# MPU_356.0 register map
Vendor: Texas Instruments
Peripheral module from a debugger description file (folder MSP432).
Registers are 32-bit, access not given, no defined reset value unless marked. A register's access mark holds for its fields unless they carry their own. Offsets are as the file gives them; lines under a group give offsets from that group; [hi:lo] are bit positions; {n}, {i} and the like mark numbered series; 'fields as' and 'values as' point back to an identical list; <NAME> marks a mode.

## MPU
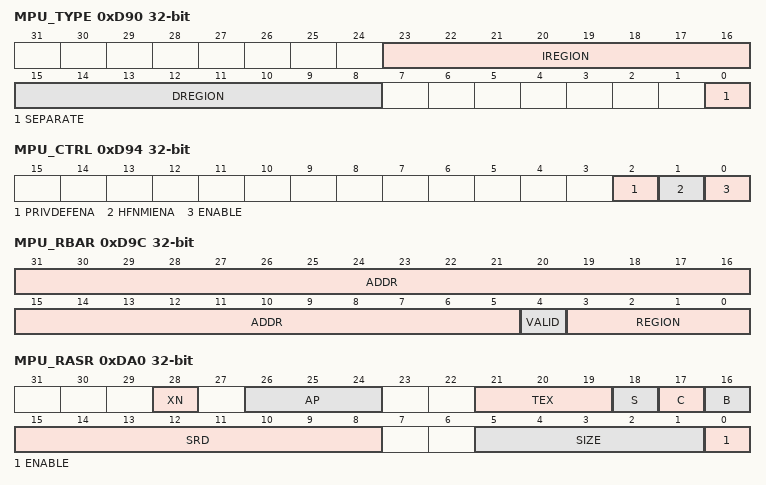
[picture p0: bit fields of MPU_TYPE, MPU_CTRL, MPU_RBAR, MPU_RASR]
0xD90 MPU_TYPE ro
  [23:16] IREGION — Because the processor core uses only a unified MPU, IREGION always contains 0x00.
  [15:8] DREGION — Number of supported MPU regions field. DREGION contains 0x08 if the implementation contains an MPU indicating eight MPU regions, otherwise it contains 0x00.
  [0] SEPARATE — Because the processor core uses only a unified MPU, SEPARATE is always 0.
0xD94 MPU_CTRL rw — MPU Control Register
  [2] PRIVDEFENA — This bit enables the default memory map for privileged access, as a background region, when the MPU is enabled. The background region acts as if it was region number 1 before any settable regions. Any region that is set up overlays this default map, and overrides it. If this bit = 0, the default memory map is disabled, and memory not covered by a region faults. This applies to memory type, Execute Never (XN), cache and shareable rules. However, this only applies to privileged mode (fetch and data access). User mode code faults unless a region has been set up for its code and data. When the MPU is disabled, the default map acts on both privileged and user mode code. XN and SO rules always apply to the System partition whether this enable is set or not. If the MPU is disabled, this bit is ignored. Reset clears the PRIVDEFENA bit.
  [1] HFNMIENA — This bit enables the MPU when in Hard Fault, NMI, and FAULTMASK escalated handlers. If this bit = 1 and the ENABLE bit = 1, the MPU is enabled when in these handlers. If this bit = 0, the MPU is disabled when in these handlers, regardless of the value of ENABLE. If this bit =1 and ENABLE = 0, behavior is Unpredictable. Reset clears the HFNMIENA bit.
  [0] ENABLE — MPU enable bit. Reset clears the ENABLE bit.
    0=en_0b0 (disable MPU); 1=en_0b1 (enable MPU)
0xD98 MPU_RNR rw — MPU Region Number Register
  [7:0] REGION — Region select field. Selects the region to operate on when using the Region Attribute and Size Register and the Region Base Address Register. It must be written first except when the address VALID + REGION fields are written, which overwrites this.
0xD9C MPU_RBAR rw — MPU Region Base Address Register
  [31:5] ADDR — Region base address field. The position of the LSB depends on the region size, so that the base address is aligned according to an even multiple of size. The power of 2 size specified by the SZENABLE field of the MPU Region Attribute and Size Register defines how many bits of base address are used.
  [4] VALID — MPU Region Number valid bit.
    0=en_0b0 (MPU Region Number Register remains unchanged and is interpreted.); 1=en_0b1 (MPU Region Number Register is overwritten by bits 3:0 (the REGION value).)
  [3:0] REGION — MPU region override field.
0xDA0 MPU_RASR rw — MPU Region Attribute and Size Register
  [28] XN — Instruction access disable bit
    0=en_0b0 (enable instruction fetches); 1=en_0b1 (disable instruction fetches)
  [26:24] AP — Data access permission field
    0=en_0b000 (Priviliged permissions: No access. User permissions: No access.); 1=en_0b001 (Priviliged permissions: Read-write. User permissions: No access.); 2=en_0b010 (Priviliged permissions: Read-write. User permissions: Read-only.); 3=en_0b011 (Priviliged permissions: Read-write. User permissions: Read-write.); 5=en_0b101 (Priviliged permissions: Read-only. User permissions: No access.); 6=en_0b110 (Priviliged permissions: Read-only. User permissions: Read-only.); 7=en_0b111 (Priviliged permissions: Read-only. User permissions: Read-only.)
  [21:19] TEX — Type extension field
  [18] S — Shareable bit
    0=en_0b0 (not shareable); 1=en_0b1 (shareable)
  [17] C — Cacheable bit
    0=en_0b0 (not cacheable); 1=en_0b1 (cacheable)
  [16] B — Bufferable bit
    0=en_0b0 (not bufferable); 1=en_0b1 (bufferable)
  [15:8] SRD — Sub-Region Disable (SRD) field. Setting an SRD bit disables the corresponding sub-region. Regions are split into eight equal-sized sub-regions. Sub-regions are not supported for region sizes of 128 bytes and less.
  [5:1] SIZE — MPU Protection Region Size Field.
    0=en_0b00000 (Reserved); 1=en_0b00001 (Reserved); 2=en_0b00010 (Reserved); 3=en_0b00011 (Reserved); 4=en_0b00100 (32B); 5=en_0b00101 (64B); 6=en_0b00110 (128B); 7=en_0b00111 (256B); 8=en_0b01000 (512B); 9=en_0b01001 (1KB); 10=en_0b01010 (2KB); 11=en_0b01011 (4KB); 12=en_0b01100 (8KB); 13=en_0b01101 (16KB); 14=en_0b01110 (32KB); 15=en_0b01111 (64KB); 16=en_0b10000 (128KB); 17=en_0b10001 (256KB); 18=en_0b10010 (512KB); 19=en_0b10011 (1MB); 20=en_0b10100 (2MB); 21=en_0b10101 (4MB); 22=en_0b10110 (8MB); 23=en_0b10111 (16MB); 24=en_0b11000 (32MB); 25=en_0b11001 (64MB); 26=en_0b11010 (128MB); 27=en_0b11011 (256MB); 28=en_0b11100 (512MB); 29=en_0b11101 (1GB); 30=en_0b11110 (2GB); 31=en_0b11111 (4GB)
  [0] ENABLE — Region enable bit.
{0xD9C+8i} MPU_RBAR_A{i} (i=1..3) — MPU Alias {i} Region Base Address register
{0xDA0+8i} MPU_RASR_A{i} (i=1..3) — MPU Alias {i} Region Attribute and Size register
